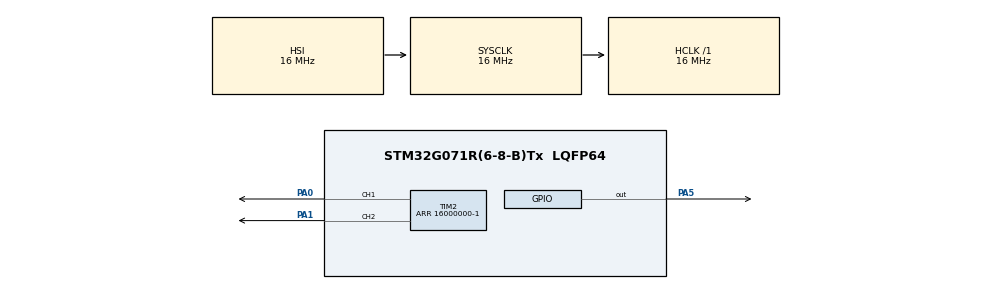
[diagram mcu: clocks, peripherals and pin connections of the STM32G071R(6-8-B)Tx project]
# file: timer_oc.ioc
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Mcu.Family=STM32G0
Mcu.Name=STM32G071R(6-8-B)Tx
Mcu.Package=LQFP64
NVIC.TIM2_IRQn=true\:0\:0\:false\:true\:true\:1\:true\:true
PA0.Signal=S_TIM2_CH1
PA1.Signal=S_TIM2_CH2
PA5.Signal=GPIO_Output
ProjectManager.HeapSize=0x200
ProjectManager.StackSize=0x400
ProjectManager.TargetToolchain=STM32CubeIDE
RCC.AHBFreq_Value=16000000
RCC.CortexFreq_Value=16000000
RCC.EXTERNAL_CLOCK_VALUE=48000
RCC.HCLKFreq_Value=16000000
RCC.HSE_VALUE=8000000
RCC.HSI_VALUE=16000000
RCC.LSE_VALUE=32768
RCC.SYSCLKFreq_VALUE=16000000
RCC.VCOOutputFreq_Value=128000000
SH.S_TIM2_CH1.0=TIM2_CH1,Output Compare1 CH1
SH.S_TIM2_CH2.0=TIM2_CH2,Output Compare2 CH2
TIM2.Channel-Output\ Compare1\ CH1=TIM_CHANNEL_1
TIM2.Channel-Output\ Compare2\ CH2=TIM_CHANNEL_2
TIM2.OCMode_1=TIM_OCMODE_TOGGLE
TIM2.OCMode_2=TIM_OCMODE_TOGGLE
TIM2.Period=16000000-1
TIM2.Pulse-Output\ Compare1\ CH1=1600000
TIM2.Pulse-Output\ Compare2\ CH2=1600000
VP_SYS_VS_DBSignals.Mode=DisableDeadBatterySignals
board=custom

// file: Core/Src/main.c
/* USER CODE BEGIN Header */
/**
  ******************************************************************************
  * @file           : main.c
  * @brief          : Main program body
  ******************************************************************************
  * @attention
  *
  * <h2><center>&copy; Copyright (c) 2019 STMicroelectronics.
  * All rights reserved.</center></h2>
  *
  * This software component is licensed by ST under BSD 3-Clause license,
  * the "License"; You may not use this file except in compliance with the
  * License. You may obtain a copy of the License at:
  *                        opensource.org/licenses/BSD-3-Clause
  *
  ******************************************************************************
  */
/* USER CODE END Header */

#include "main.h"

TIM_HandleTypeDef htim2;

/* USER CODE BEGIN PV */
uint32_t pulse1_value=1600000,pulse2_value=160000,ccr_content1,ccr_content2;
/* USER CODE END PV */

void SystemClock_Config(void);
static void MX_GPIO_Init(void);
static void MX_TIM2_Init(void);
static void MX_NVIC_Init(void);

int main(void)
{

  /* MCU Configuration--------------------------------------------------------*/

  /* Reset of all peripherals, Initializes the Flash interface and the Systick. */
  HAL_Init();

  /* Configure the system clock */
  SystemClock_Config();

  /* Initialize all configured peripherals */
  MX_GPIO_Init();
  MX_TIM2_Init();

  /* Initialize interrupts */
  MX_NVIC_Init();
  /* USER CODE BEGIN 2 */
HAL_TIM_OC_Start_IT(&htim2, TIM_CHANNEL_1);
HAL_TIM_OC_Start_IT(&htim2, TIM_CHANNEL_2);
  /* USER CODE END 2 */

  /* Infinite loop */
  while (1)
  {

  }
}

void SystemClock_Config(void)
{
  RCC_OscInitTypeDef RCC_OscInitStruct = {0};
  RCC_ClkInitTypeDef RCC_ClkInitStruct = {0};

  /** Configure the main internal regulator output voltage
  */
  HAL_PWREx_ControlVoltageScaling(PWR_REGULATOR_VOLTAGE_SCALE1);
  /** Initializes the CPU, AHB and APB busses clocks
  */
  RCC_OscInitStruct.OscillatorType = RCC_OSCILLATORTYPE_HSI;
  RCC_OscInitStruct.HSIState = RCC_HSI_ON;
  RCC_OscInitStruct.HSIDiv = RCC_HSI_DIV1;
  RCC_OscInitStruct.HSICalibrationValue = RCC_HSICALIBRATION_DEFAULT;
  RCC_OscInitStruct.PLL.PLLState = RCC_PLL_NONE;
  if (HAL_RCC_OscConfig(&RCC_OscInitStruct) != HAL_OK)
  {
    Error_Handler();
  }
  /** Initializes the CPU, AHB and APB busses clocks
  */
  RCC_ClkInitStruct.ClockType = RCC_CLOCKTYPE_HCLK|RCC_CLOCKTYPE_SYSCLK
                              |RCC_CLOCKTYPE_PCLK1;
  RCC_ClkInitStruct.SYSCLKSource = RCC_SYSCLKSOURCE_HSI;
  RCC_ClkInitStruct.AHBCLKDivider = RCC_SYSCLK_DIV1;
  RCC_ClkInitStruct.APB1CLKDivider = RCC_HCLK_DIV1;

  if (HAL_RCC_ClockConfig(&RCC_ClkInitStruct, FLASH_LATENCY_0) != HAL_OK)
  {
    Error_Handler();
  }
}

/**
  * @brief NVIC Configuration.
  * @retval None
  */
static void MX_NVIC_Init(void)
{
  /* TIM2_IRQn interrupt configuration */
  HAL_NVIC_SetPriority(TIM2_IRQn, 0, 0);
  HAL_NVIC_EnableIRQ(TIM2_IRQn);
}

static void MX_TIM2_Init(void)
{

  TIM_MasterConfigTypeDef sMasterConfig = {0};
  TIM_OC_InitTypeDef sConfigOC = {0};

  htim2.Instance = TIM2;
  htim2.Init.Prescaler = 0;
  htim2.Init.CounterMode = TIM_COUNTERMODE_UP;
  htim2.Init.Period = 16000000-1;
  htim2.Init.ClockDivision = TIM_CLOCKDIVISION_DIV1;
  htim2.Init.AutoReloadPreload = TIM_AUTORELOAD_PRELOAD_DISABLE;
  if (HAL_TIM_OC_Init(&htim2) != HAL_OK)
  {
    Error_Handler();
  }
  sMasterConfig.MasterOutputTrigger = TIM_TRGO_RESET;
  sMasterConfig.MasterSlaveMode = TIM_MASTERSLAVEMODE_DISABLE;
  if (HAL_TIMEx_MasterConfigSynchronization(&htim2, &sMasterConfig) != HAL_OK)
  {
    Error_Handler();
  }
  sConfigOC.OCMode = TIM_OCMODE_TOGGLE;
  sConfigOC.Pulse = 1600000;
  sConfigOC.OCPolarity = TIM_OCPOLARITY_HIGH;
  sConfigOC.OCFastMode = TIM_OCFAST_DISABLE;
  if (HAL_TIM_OC_ConfigChannel(&htim2, &sConfigOC, TIM_CHANNEL_1) != HAL_OK)
  {
    Error_Handler();
  }
  if (HAL_TIM_OC_ConfigChannel(&htim2, &sConfigOC, TIM_CHANNEL_2) != HAL_OK)
  {
    Error_Handler();
  }
  HAL_TIM_MspPostInit(&htim2);

}

static void MX_GPIO_Init(void)
{
  GPIO_InitTypeDef GPIO_InitStruct = {0};

  /* GPIO Ports Clock Enable */
  __HAL_RCC_GPIOA_CLK_ENABLE();

  /*Configure GPIO pin Output Level */
  HAL_GPIO_WritePin(GPIOA, GPIO_PIN_5, GPIO_PIN_RESET);

  /*Configure GPIO pin : PA5 */
  GPIO_InitStruct.Pin = GPIO_PIN_5;
  GPIO_InitStruct.Mode = GPIO_MODE_OUTPUT_PP;
  GPIO_InitStruct.Pull = GPIO_NOPULL;
  GPIO_InitStruct.Speed = GPIO_SPEED_FREQ_LOW;
  HAL_GPIO_Init(GPIOA, &GPIO_InitStruct);

}

/* USER CODE BEGIN 4 */
void HAL_TIM_OC_DelayElapsedCallback(TIM_HandleTypeDef *htim)
{
	if(htim->Channel==HAL_TIM_ACTIVE_CHANNEL_1)
	{
	ccr_content1 = HAL_TIM_ReadCapturedValue(htim, TIM_CHANNEL_1);
	__HAL_TIM_SET_COMPARE(htim,TIM_CHANNEL_1,ccr_content1+pulse1_value);
	}
	if(htim->Channel==HAL_TIM_ACTIVE_CHANNEL_2)
		{
		ccr_content2 = HAL_TIM_ReadCapturedValue(htim, TIM_CHANNEL_2);
		__HAL_TIM_SET_COMPARE(htim,TIM_CHANNEL_1,ccr_content2+pulse2_value);
	}
}
/* USER CODE END 4 */

void Error_Handler(void)
{
}

/************************ (C) COPYRIGHT STMicroelectronics *****END OF FILE****/
